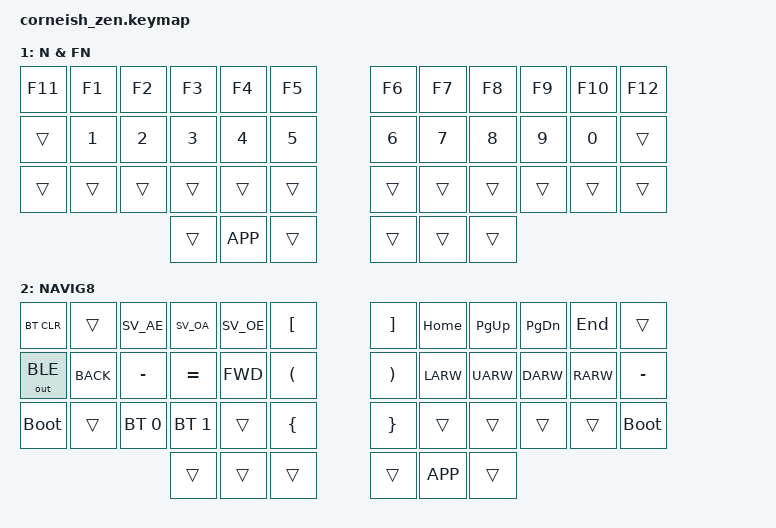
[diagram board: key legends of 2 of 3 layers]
/*
*
* Copyright (c) 2021 Darryl deHaan
* SPDX-License-Identifier: MIT
*
*/

#include <behaviors.dtsi>
#include <dt-bindings/zmk/keys.h>
#include <dt-bindings/zmk/bt.h>
#include <dt-bindings/zmk/outputs.h>

#define HRML(k1,k2,k3,k4) &ht LCTRL k1  &ht LSHFT k2  &ht LALT k3  &ht LGUI k4
#define HRMR(k1,k2,k3,k4) &ht RGUI k1  &ht RALT k2  &ht RSHFT k3  &ht RCTRL k4
#define SV_OE RA(P)
#define SV_AE RA(Q)
#define SV_OA RA(W)
#define K_FWD K_FORWARD
#define BT_0 BT_SEL 0
#define BT_1 BT_SEL 1


/ {
  chosen {
    zmk,matrix_transform = &default_transform;
    //zmk,matrix_transform = &five_column_transform;
  };

  behaviors {
        ht: hold_tap {
            label = "hold_tap";
            compatible = "zmk,behavior-hold-tap";
            #binding-cells = <2>;
            flavor = "tap-preferred";
            tapping-term-ms = <220>;
            quick-tap-ms = <150>;
            global-quick-tap;
            bindings = <&kp>, <&kp>;
        };
    };
  keymap {
        compatible = "zmk,keymap";

        default_layer {
                label = "DVORAK";
// -----------------------------------------------------------------------------------------
// |  `   |  '  |  ,  |  .  |  P  |  Y  |   |  F  |  G   |  C  |  R  |  L  |  /   |
// | ESC  |  A  |  O  |  E  |  U  |  I  |   |  D  |  H   |  T  |  N  |  S  |  =   |
// |  -   |  ;  |  Q  |  J  |  K  |  X  |   |  B  |  M   |  W  |  V  |  Z  |  \   |
//                    | GUI | LWR | SPC |   | ENT | RSE  | ALT |
                        bindings = <
   &kp GRAVE &kp SQT  &kp COMMA &kp DOT &kp P    &kp Y   &kp F           &kp G       &kp C    &kp R   &kp L  &kp FSLH
   &kp ESC   HRML(A,      O,        E,      U)   &kp I   &kp D           HRMR(H,         T,       N,      S) &kp EQUAL
   &kp MINUS &kp SEMI &kp Q     &kp J   &kp K    &kp X   &kp B           &kp M       &kp W    &kp V   &kp Z  &kp BSLH
                                        &kp DEL  &kp SPACE  &lt 2 BSPC   &lt 1 ENTER &kp TAB  &kp INS
                >;
        };
        lower_layer {
                label = "N & FN";
// -----------------------------------------------------------------------------------------
// | F11  |  F1 | F2  | F3  | F4  | F5  |   | F6  | F7  | F8  | F9  | F10 | F12  |
// |      |  1  |  2  |  3  |  4  |  5  |   |  6  |  7  |  8  |  9  |  0  |      |
// |      |     |     |     |     |     |   |     |     |     |     |     |      |
//                    |     |     |     |   |     |     |     |
                        bindings = <
   &kp F11   &kp F1       &kp F2       &kp F3       &kp F4       &kp F5         &kp F6   &kp F7   &kp F8 &kp F9    &kp F10 &kp F12
   &trans    &kp N1       &kp N2       &kp N3       &kp N4       &kp N5         &kp N6   &kp N7   &kp N8 &kp N9    &kp N0  &trans
   &trans    &trans       &trans       &trans       &trans       &trans         &trans   &trans   &trans &trans    &trans  &trans
                          	       &trans       &kp K_APP    &trans         &trans   &trans   &trans
                >;
        };

        raise_layer {
                label = "NAVIG8";
// -----------------------------------------------------------------------------------------
// |BT:CLR|     |  Ä  |  Å  |  Ö  |  [  |   |  ]  | HOME| PGUP| PGDN| END |      |
// |      | BACK|     |  -  | FWD |  (  |   |  )  | LEFT|  UP | DOWN|RIGHT|   -  |
// |      |     |     |     |     |  {  |   |  }  |     |     |     |     |      |
//                    |     |     |     |   |     |     |     |
                        bindings = <
   &bt BT_CLR     &trans     &kp SV_AE  &kp SV_OA   &kp SV_OE &kp LBKT    &kp RBKT    &kp HOME  &kp PG_UP &kp PG_DN &kp END   &trans
   &out OUT_BLE   &kp K_BACK &kp MINUS  &kp EQUAL   &kp K_FWD &kp LPAR    &kp RPAR    &kp LARW  &kp UARW  &kp DARW  &kp RARW  &kp MINUS
   &bootloader    &trans     &bt BT_0   &bt BT_1    &trans    &kp LBRC    &kp RBRC    &trans    &trans    &trans    &trans    &bootloader
                    	                &trans      &trans    &trans      &trans      &kp K_APP &trans
                        >;
                };
        };
};
